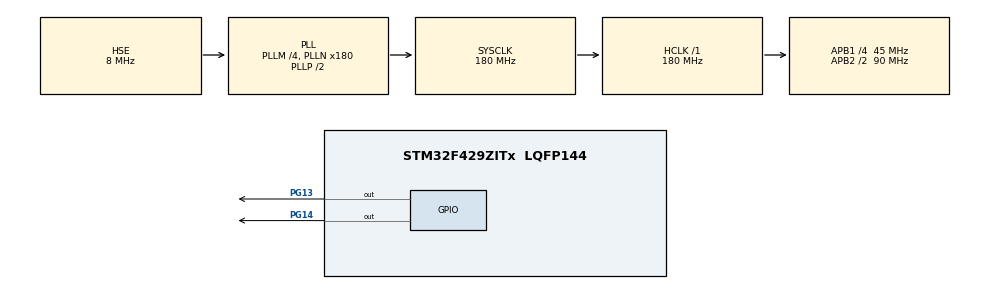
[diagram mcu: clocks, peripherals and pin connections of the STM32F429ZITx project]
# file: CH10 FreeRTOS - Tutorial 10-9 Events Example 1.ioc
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FREERTOS.Events01=myEvent01,Dynamic,NULL
FREERTOS.Tasks01=defaultTask,24,128,StartDefaultTask,Default,NULL,Dynamic,NULL,NULL;myTask02,32,128,StartTask02,Default,NULL,Dynamic,NULL,NULL
FREERTOS.configUSE_NEWLIB_REENTRANT=1
Mcu.Family=STM32F4
Mcu.Name=STM32F429ZITx
Mcu.Package=LQFP144
NVIC.PriorityGroup=NVIC_PRIORITYGROUP_4
NVIC.TIM6_DAC_IRQn=true\:0\:0\:true\:false\:true\:false\:false\:true\:true
NVIC.TimeBase=TIM6_DAC_IRQn
NVIC.TimeBaseIP=TIM6
PG13.Signal=GPIO_Output
PG14.Signal=GPIO_Output
PH0/OSC_IN.Mode=HSE-External-Oscillator
PH0/OSC_IN.Signal=RCC_OSC_IN
PH1/OSC_OUT.Mode=HSE-External-Oscillator
PH1/OSC_OUT.Signal=RCC_OSC_OUT
ProjectManager.HeapSize=0x200
ProjectManager.StackSize=0x400
ProjectManager.TargetToolchain=STM32CubeIDE
RCC.48MHZClocksFreq_Value=51428571.428571425
RCC.AHBFreq_Value=180000000
RCC.APB1CLKDivider=RCC_HCLK_DIV4
RCC.APB1Freq_Value=45000000
RCC.APB1TimFreq_Value=90000000
RCC.APB2CLKDivider=RCC_HCLK_DIV2
RCC.APB2Freq_Value=90000000
RCC.APB2TimFreq_Value=180000000
RCC.CortexFreq_Value=180000000
RCC.HCLKFreq_Value=180000000
RCC.HSE_VALUE=8000000
RCC.HSI_VALUE=16000000
RCC.LSE_VALUE=32768
RCC.PLLM=4
RCC.PLLN=180
RCC.PLLQ=7
RCC.PLLSourceVirtual=RCC_PLLSOURCE_HSE
RCC.SYSCLKFreq_VALUE=180000000
RCC.SYSCLKSource=RCC_SYSCLKSOURCE_PLLCLK
RCC.VCOOutputFreq_Value=360000000
VP_FREERTOS_VS_CMSIS_V2.Mode=CMSIS_V2
VP_SYS_VS_tim6.Mode=TIM6
board=STM32F429I-DISC1

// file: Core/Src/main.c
/* USER CODE BEGIN Header */
/**
  ******************************************************************************
  * @file           : main.c
  * @brief          : Main program body
  ******************************************************************************
  * @attention
  *
  * Copyright (c) 2024 STMicroelectronics.
  * All rights reserved.
  *
  * This software is licensed under terms that can be found in the LICENSE file
  * in the root directory of this software component.
  * If no LICENSE file comes with this software, it is provided AS-IS.
  *
  ******************************************************************************
  */

	/***************************** Tutorial Tags ******************************
		 FreeRTOS
		 Task management (priority, state)
		 Events in FreeRTOS
		 GPIO output
	 **************************************************************************/

	/* 10.4 Events in FreeRTOS: **************************************
	 * Tutorial -10-9: The first event example in FreeRTOS

    In this tutorial, we create an additional task
	named myTask02 apart from the default task. The priority of this task is set to
	osPriorityAboveNormal, which is higher than the priority of the default task. As
	the code is executed, the green LED on the STM32F4 board is toggled, cnt variable
	is set to 1, event flag is cleared and then set to FLAG2, and the string “defaultTask”
	is printed by the default task every 0.5 s if the event flag is FLAG1. The red LED
	on the STM32F4 board is toggled, cnt variable is set to 2, event flag is cleared and
	then set to FLAG1, and the string “myTask02” is printed by the task myTask02 every
	0.5 s if the event flag is FLAG2.

	When the code in this tutorial 10.9 is executed, the event flag is set to FLAG1 at the
	beginning of the function StartTask02. The task myTask02 has higher priority
	than default task. Therefore, it must be called first. However, both tasks wait for the
	event flag which is initially set to FLAG1. Hence, the default task is called first. It
	toggles the green LED on the STM32F4 board and sets the event flag to FLAG2. As
	soon as the event flag is set to FLAG2, myTask02 gets the precedence. Therefore, it
	is called before the default task yields since it has higher priority. As a result, the
	red LED on the STM32F4 board is toggled; the event flag is set to FLAG1; the string
	“myTask02” is printed. Then, myTask02 yields. Finally, the string “defaultTask” is
	printed, the default task yields, and both tasks wait for 0.5 s.We should modify ITM
	properties as explained in Sect. 3.4.1.1 of the book to observe printing results in this example

	***************************************************************************/

/* USER CODE END Header */
#include "main.h"
#include "cmsis_os.h"

/* USER CODE BEGIN Includes */
#include "stdio.h"
#include "string.h"
/* USER CODE END Includes */

/* USER CODE BEGIN PD */
#define FLAG1 0x01
#define FLAG2 0x10
/* USER CODE END PD */

/* Definitions for defaultTask */
osThreadId_t defaultTaskHandle;
const osThreadAttr_t defaultTask_attributes = {
		.name = "defaultTask",
		.stack_size = 128 * 4,
		.priority = (osPriority_t) osPriorityNormal,
};
/* Definitions for myTask02 */
osThreadId_t myTask02Handle;

const osThreadAttr_t myTask02_attributes = {
		.name = "myTask02",
		.stack_size = 128 * 4,
		.priority = (osPriority_t) osPriorityAboveNormal,
};
/* Definitions for myEvent01 */
osEventFlagsId_t myEvent01Handle;
const osEventFlagsAttr_t myEvent01_attributes = {
		.name = "myEvent01"
};
/* USER CODE BEGIN PV */

uint8_t cn;

/* USER CODE END PV */

void SystemClock_Config(void);
static void MX_GPIO_Init(void);
void StartDefaultTask(void *argument);
void StartTask02(void *argument);

/* USER CODE BEGIN 0 */
/*Function needed to use printf on CONSOLE*/
int _write(int file, char *ptr, int len){
	int i = 0;
	for (i=0; i<len; i++)
		ITM_SendChar((*ptr++));
	return len;
}
/* USER CODE END 0 */

int main(void)
{

  /* MCU Configuration--------------------------------------------------------*/

  /* Reset of all peripherals, Initializes the Flash interface and the Systick. */
  HAL_Init();

  /* Configure the system clock */
  SystemClock_Config();

  /* Initialize all configured peripherals */
  MX_GPIO_Init();
  /* USER CODE BEGIN 2 */
  printf("PROGRAM START \n\r");
  /* USER CODE END 2 */

  /* Init scheduler */
  osKernelInitialize();

  /* Create the thread(s) */
  /* creation of defaultTask */
  defaultTaskHandle = osThreadNew(StartDefaultTask, NULL, &defaultTask_attributes);

  /* creation of myTask02 */
  myTask02Handle = osThreadNew(StartTask02, NULL, &myTask02_attributes);

  /* Create the event(s) */
  /* creation of myEvent01 */
  myEvent01Handle = osEventFlagsNew(&myEvent01_attributes);

  /* Start scheduler */
  osKernelStart();

  /* We should never get here as control is now taken by the scheduler */
  /* Infinite loop */
  while (1)
  {

  }
}

void SystemClock_Config(void)
{
  RCC_OscInitTypeDef RCC_OscInitStruct = {0};
  RCC_ClkInitTypeDef RCC_ClkInitStruct = {0};

  /** Configure the main internal regulator output voltage
  */
  __HAL_RCC_PWR_CLK_ENABLE();
  __HAL_PWR_VOLTAGESCALING_CONFIG(PWR_REGULATOR_VOLTAGE_SCALE1);

  /** Initializes the RCC Oscillators according to the specified parameters
  * in the RCC_OscInitTypeDef structure.
  */
  RCC_OscInitStruct.OscillatorType = RCC_OSCILLATORTYPE_HSE;
  RCC_OscInitStruct.HSEState = RCC_HSE_ON;
  RCC_OscInitStruct.PLL.PLLState = RCC_PLL_ON;
  RCC_OscInitStruct.PLL.PLLSource = RCC_PLLSOURCE_HSE;
  RCC_OscInitStruct.PLL.PLLM = 4;
  RCC_OscInitStruct.PLL.PLLN = 180;
  RCC_OscInitStruct.PLL.PLLP = RCC_PLLP_DIV2;
  RCC_OscInitStruct.PLL.PLLQ = 7;
  if (HAL_RCC_OscConfig(&RCC_OscInitStruct) != HAL_OK)
  {
    Error_Handler();
  }

  /** Activate the Over-Drive mode
  */
  if (HAL_PWREx_EnableOverDrive() != HAL_OK)
  {
    Error_Handler();
  }

  /** Initializes the CPU, AHB and APB buses clocks
  */
  RCC_ClkInitStruct.ClockType = RCC_CLOCKTYPE_HCLK|RCC_CLOCKTYPE_SYSCLK
                              |RCC_CLOCKTYPE_PCLK1|RCC_CLOCKTYPE_PCLK2;
  RCC_ClkInitStruct.SYSCLKSource = RCC_SYSCLKSOURCE_PLLCLK;
  RCC_ClkInitStruct.AHBCLKDivider = RCC_SYSCLK_DIV1;
  RCC_ClkInitStruct.APB1CLKDivider = RCC_HCLK_DIV4;
  RCC_ClkInitStruct.APB2CLKDivider = RCC_HCLK_DIV2;

  if (HAL_RCC_ClockConfig(&RCC_ClkInitStruct, FLASH_LATENCY_5) != HAL_OK)
  {
    Error_Handler();
  }
}

static void MX_GPIO_Init(void)
{
  GPIO_InitTypeDef GPIO_InitStruct = {0};

  /* GPIO Ports Clock Enable */
  __HAL_RCC_GPIOH_CLK_ENABLE();
  __HAL_RCC_GPIOG_CLK_ENABLE();

  /*Configure GPIO pin Output Level */
  HAL_GPIO_WritePin(GPIOG, GPIO_PIN_13|GPIO_PIN_14, GPIO_PIN_RESET);

  /*Configure GPIO pins : PG13 PG14 */
  GPIO_InitStruct.Pin = GPIO_PIN_13|GPIO_PIN_14;
  GPIO_InitStruct.Mode = GPIO_MODE_OUTPUT_PP;
  GPIO_InitStruct.Pull = GPIO_NOPULL;
  GPIO_InitStruct.Speed = GPIO_SPEED_FREQ_LOW;
  HAL_GPIO_Init(GPIOG, &GPIO_InitStruct);

}

void StartDefaultTask(void *argument)
{
  /* USER CODE BEGIN 5 */

  /* Infinite loop */
  for(;;)
  {
	  /*Waiting for FLAG 1 to be set by the other DefaultTask*/
	  osEventFlagsWait(myEvent01Handle, FLAG1, osFlagsWaitAny, osWaitForever);

	  // Toggle green led
	  HAL_GPIO_TogglePin(GPIOG, GPIO_PIN_13);
	  cn = 1;

	  /*Clear Flag 1 and set Flag 2 to jump to Task02*/
	  osEventFlagsClear(myEvent01Handle , FLAG1);
	  osEventFlagsSet(myEvent01Handle, FLAG2);

	  printf("DefaultTask %u\n\r", cn);

	  osDelay(1000);
  }
  /* USER CODE END 5 */
}

void StartTask02(void *argument)
{
  /* USER CODE BEGIN StartTask02 */
  /*Set Flag 1*/
  osEventFlagsSet(myEvent01Handle, FLAG1);
  /* Infinite loop */
  for(;;)
  {
	  /*Waiting for FLAG 2 to be set by the other DefaultTask*/
	  osEventFlagsWait(myEvent01Handle, FLAG2, osFlagsWaitAny, osWaitForever);

	  // Toggle red led
	  HAL_GPIO_TogglePin(GPIOG, GPIO_PIN_14);
	  cn = 2;

	  // Clear FLAG2 and Set FLAG1 to jump to Default task
	  osEventFlagsClear(myEvent01Handle, FLAG2);
	  osEventFlagsSet(myEvent01Handle, FLAG1);

	  printf("Task02 \n\r");

	 /*Now time for Task 02 to yield*/
	  osDelay(1000);
  }
  /* USER CODE END StartTask02 */
}

void HAL_TIM_PeriodElapsedCallback(TIM_HandleTypeDef *htim)
{
  if (htim->Instance == TIM6) {
    HAL_IncTick();
  }
}

void Error_Handler(void)
{
  __disable_irq();
  while (1)
  {
  }
}
